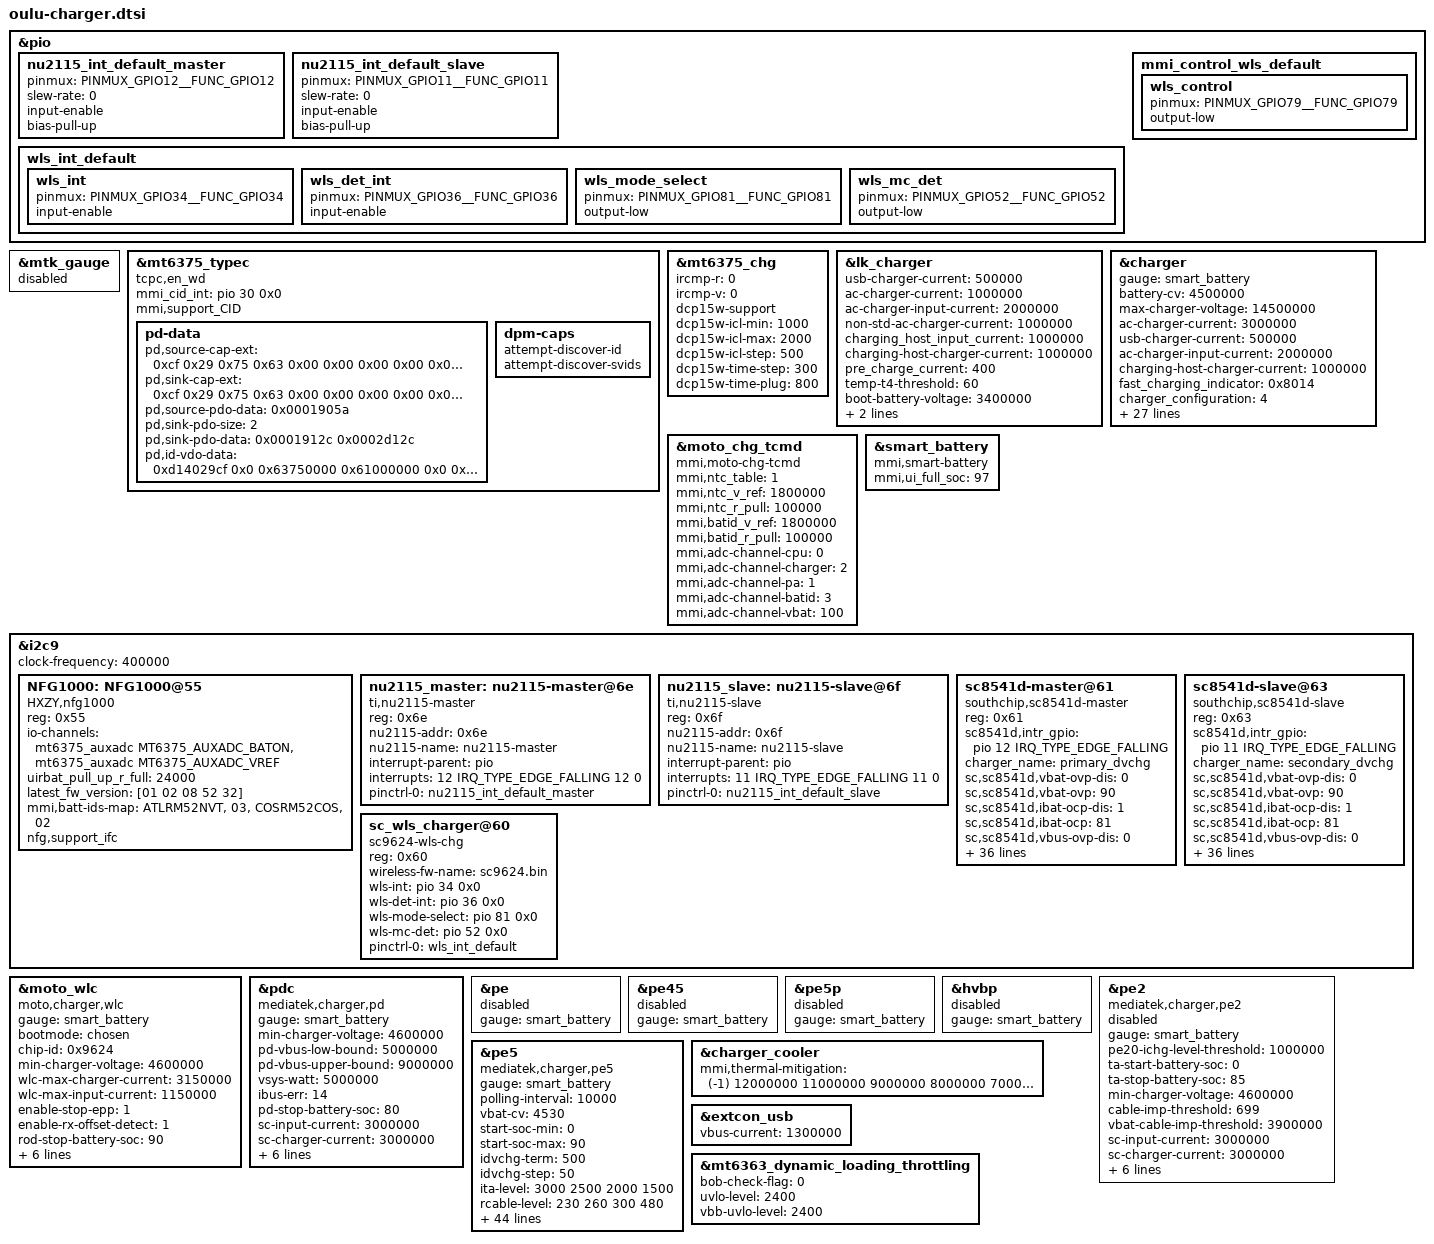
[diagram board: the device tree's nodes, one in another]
/*
 * Copyright (c) 2021 MediaTek Inc.
 *
 * This program is free software; you can redistribute it and/or modify
 * it under the terms of the GNU General Public License version 2 as
 * published by the Free Software Foundation.
 *
 * This program is distributed in the hope that it will be useful,
 * but WITHOUT ANY WARRANTY; without even the implied warranty of
 * MERCHANTABILITY or FITNESS FOR A PARTICULAR PURPOSE.  See the
 * GNU General Public License for more details.
 */
#include <dt-bindings/iio/adc/mediatek,mt6375_auxadc.h>
#include <dt-bindings/iio/adc/mediatek,mt6375_adc.h>
#include <dt-bindings/iio/mt635x-auxadc.h>

&pio {
	nu2115_int_default_master: nu2115_int_default_master {
		pinmux = <PINMUX_GPIO12__FUNC_GPIO12>;
		slew-rate= <0>;
		input-enable;
		bias-pull-up;
	};

	nu2115_int_default_slave: nu2115_int_default_slave {
		pinmux = <PINMUX_GPIO11__FUNC_GPIO11>;
		slew-rate= <0>;
		input-enable;
		bias-pull-up;
	};

	wls_int_default: wls_int_default {
		wls_int {
			pinmux = <PINMUX_GPIO34__FUNC_GPIO34>;
			input-enable;
			//bias-pull-up;
		};
		wls_det_int {
			pinmux = <PINMUX_GPIO36__FUNC_GPIO36>;
			input-enable;
			//bias-disable;
		};
		wls_mode_select {
			pinmux = <PINMUX_GPIO81__FUNC_GPIO81>;
			output-low;
		};
		wls_mc_det {
			pinmux = <PINMUX_GPIO52__FUNC_GPIO52>;
			output-low;
		};
	};

	mmi_control_wls_default: mmi_control_wls_default {
		wls_control {
			pinmux = <PINMUX_GPIO79__FUNC_GPIO79>;
			output-low;
		};
	};
};

&mtk_gauge {
	status = "disabled";
};


&mt6375_typec {
       tcpc,en_wd;
       mmi_cid_int = <&pio 30 0x0>;
       mmi,support_CID;
};

&mt6375_chg {
	ircmp-r = <0>;
	ircmp-v = <0>;

	dcp15w-support;
	dcp15w-icl-min = <1000>; //mA
	dcp15w-icl-max = <2000>; //mA
	dcp15w-icl-step = <500>; //mA
	dcp15w-time-step = <300>; //ms
	dcp15w-time-plug = <800>; //ms
};

&lk_charger {
	/* charging current */
	usb-charger-current = <500000>;
	ac-charger-current = <1000000>;
	ac-charger-input-current = <2000000>;
	non-std-ac-charger-current = <1000000>;
	charging_host_input_current = <1000000>;
	charging-host-charger-current = <1000000>;
	pre_charge_current = <400>;

	temp-t4-threshold = <60>;
	boot-battery-voltage = <3400000>;
	boot-battery-voltage-max = <3400000>;
	/*boot battery voltage when using AC charger*/
	ac_charger_boot_battery_voltage = <3300000>;
};

/*
&mtk_ctd {
	bootmode = <&chosen>;
};
*/

&charger {
	gauge = <&smart_battery>;
	battery-cv = <4500000>;
	max-charger-voltage = <14500000>;
	ac-charger-current = <3000000>;
	usb-charger-current = <500000>;
	ac-charger-input-current = <2000000>;
	charging-host-charger-current = <1000000>;

	/*pe5 && pdc && pe2 && wlc*/
	fast_charging_indicator = <0x8014>;
	/*swchg + 2CP*/
	charger_configuration= <4>;

	wireless_factory_max_current = <3000000>;
	wireless_factory_max_input_current = <600000>;

	disable-aicl;

	enable-pdtest-mode = <1>;

	mmi,enable-mux;
	mmi,typec-mos-only;

	mmi,enable-ifc;

	// mmi,mux_wls_switch_en = <&pio 99 0x0>;
	// mmi,mux_switch_enn_en = <&pio 32 0x0>;

	/* dynamic mivr */
	enable-dynamic-mivr;

	/*mmi config*/
	mmi,typec-rp-max-current = <2000000>;

	mmi,enable-charging-limit;
	mmi,upper-limit-capacity = <65>;
	mmi,lower-limit-capacity = <60>;
	mmi,min-cp-therm-current-ua = <1000000>;

	mmi,pd-pmax-mw = <68000>;
	mmi,pd_vbus_low_bound = <5000000>;
	mmi,pd_vbus_upper_bound = <9000000>;

	mmi,mmi-temp-zones = <0 4200 1020 0>,
				<10 4250 5100 2550>,
				<15 0 5100 5100>,
				<45 4250 12000 10000>,
				<45 4300 10000 8000>,
				<45 4400 8000 6000>,
				<45 4500 6000 5100>,
				<60 4200 5100 0>;
	mmi,mmi-ffc-zones = <0 4200 255>,
				<10 4500 255>,
				<15 4500 255>,
				<25 4530 930>,
				<35 4530 1018>,
				<45 4530 1389>,
				<60 4200 255>;
	mmi,mmi-normal-zones = <0 4200 255>,
				<10 4500 255>,
				<15 4500 255>,
				<25 4500 255>,
				<35 4500 255>,
				<45 4500 510>,
				<60 4200 255>;
};

/*
&mt6375_chg {
	mmi,mux_otg_switch_en = <&pio 99 0x0>;
};
*/
&moto_chg_tcmd {
	compatible = "mmi,moto-chg-tcmd";
	status = "okay";

	mmi,ntc_table = <1>;
	mmi,ntc_v_ref = <1800000>;
	mmi,ntc_r_pull = <100000>;

	mmi,batid_v_ref = <1800000>;
	mmi,batid_r_pull = <100000>;

	mmi,adc-channel-cpu = <0>;
	mmi,adc-channel-charger = <2>;
	mmi,adc-channel-pa = <1>;
	mmi,adc-channel-batid = <3>;
	mmi,adc-channel-vbat = <100>;
};

&smart_battery {
	status = "okay";
	compatible = "mmi,smart-battery";
	mmi,ui_full_soc = <97>;
};

&i2c9 {
	clock-frequency = <400000>;
	status = "okay";

	NFG1000: NFG1000@55 {
		compatible = "HXZY,nfg1000";
		reg = <0x55>;

		io-channels = <&mt6375_auxadc MT6375_AUXADC_BATON>,
		              <&mt6375_auxadc MT6375_AUXADC_VREF>;
		io-channel-names = "bat_temp", "vref";

		uirbat_pull_up_r_full = <24000>;/*24k*/

		latest_fw_version = [01 02 08 52 32];
		mmi,batt-ids-map = "ATLRM52NVT","03",
				   "COSRM52COS","02";
		nfg,support_ifc;
	};

	nu2115_master:nu2115-master@6e {
		status = "okay";
		compatible = "ti,nu2115-master";
		reg = <0x6e>;

		nu2115-addr = <0x6e>;
		nu2115-name = "nu2115-master";

		interrupt-parent = <&pio>;
		interrupts = <12 IRQ_TYPE_EDGE_FALLING 12 0>;
		interrupt-names = "nu2115_irq_master";

		pinctrl-names = "default";
		pinctrl-0 = <&nu2115_int_default_master>;
	};

	nu2115_slave:nu2115-slave@6f {
		status = "okay";
		compatible = "ti,nu2115-slave";
		reg = <0x6f>;

		nu2115-addr = <0x6f>;
		nu2115-name = "nu2115-slave";

		interrupt-parent = <&pio>;
		interrupts = <11 IRQ_TYPE_EDGE_FALLING 11 0>;
		interrupt-names = "nu2115_irq_slave";

		pinctrl-names = "default";
		pinctrl-0 = <&nu2115_int_default_slave>;
	};

	sc8541d-master@61{
		compatible = "southchip,sc8541d-master";
		reg = <0x61>;
		sc8541d,intr_gpio = <&pio 12 IRQ_TYPE_EDGE_FALLING>;
		charger_name = "primary_dvchg";

		sc,sc8541d,vbat-ovp-dis = <0>;
		sc,sc8541d,vbat-ovp = <90>; /*3840 + val * 10*/
		sc,sc8541d,ibat-ocp-dis = <1>;
		sc,sc8541d,ibat-ocp = <81>; /*val * 100*/
		sc,sc8541d,vbus-ovp-dis = <0>;
		sc,sc8541d,vbus-ovp = <3>; /*10500 + val * 500*/
		sc,sc8541d,vac-ovp-dis = <0>;
		sc,sc8541d,vac-ovp = <2>; /*0:6.5V 1:11V 2:12V 3:13V 4:14V 5~7:15V*/
		sc,sc8541d,ibus-ocp-dis = <1>;
		sc,sc8541d,ibus-ocp = <100>; /*val * 50*/
		sc,sc8541d,pmid2out-ovp-dis = <0>;
		sc,sc8541d,pmid2out-ovp = <0>; /*400 + val * 100*/
		sc,sc8541d,pmid2out-uvp-dis = <0>;
		sc,sc8541d,pmid2out-uvp = <1>; /*100 + val * 50*/
		sc,sc8541d,ibatreg = <0>; /*200 + val * 100*/
		sc,sc8541d,ibusreg = <0>; /*100 + val * 50*/
		sc,sc8541d,vbatreg = <0>; /*50 + val * 50*/
		sc,sc8541d,tdiereg = <1>; /*0:90°C 1:100°C 2:110°C 3:120°C*/
		sc,sc8541d,them-flt = <24>; /*val * 25*/
		sc,sc8541d,ibat-sns-res = <0>; /*0:2hmo 1:5hmo*/
		sc,sc8541d,pmid-pd-en = <0>;
		sc,sc8541d,vbus-pd-en = <0>;
		sc,sc8541d,work-mode = <0>; /*0: 2:1charge   1: 1:1charge
		                             2: 1:2converte 3: 1:1converte*/
		sc,sc8541d,ss-timeout = <7>; /*0:disable 1:10ms 2:20ms 3:400ms
		                            4:80ms 5:320ms 6:1.28s 7:10.24s*/
		sc,sc8541d,wd-timeout-dis = <1>;
		sc,sc8541d,wd-timeout = <0>; /*0:0.5s 1:1s 2:5s 3:30s*/
		sc,sc8541d,vout-ovp-dis = <0>;
		sc,sc8541d,vout-ovp = <1>; /*0:4700mv 1:5000mv*/
		sc,sc8541d,fsw-freq = <7>; /*500 + val * 100*/
		sc,sc8541d,pin-diag-fall-dis = <0>;
		sc,sc8541d,them-flt-dis = <1>;
		sc,sc8541d,tshut-dis = <1>;
		sc,sc8541d,ibus-ucp-dis = <0>;
		sc,sc8541d,ibat-reg-dis = <0>;
		sc,sc8541d,ibus-reg-dis = <0>;
		sc,sc8541d,vbat-reg-dis = <0>;
		sc,sc8541d,tdie-reg-dis = <1>;
		sc,sc8541d,ibat-ocp-dg = <0>; /*0:80us 1:320us 2:640us 3:5ms*/
		sc,sc8541d,ibus-ucp-fall-dg = <1>; /*0:8us 1:5ms 2:40ms 3:160ms*/
		sc,sc8541d,ibus-ocp-dg = <0>; /*0:80us 1:320us 2:640us 3:5ms*/
		sc,sc8541d,vbat-ovp-dg = <0>; /*0:8us 1:640us 2:1.28ms 3:5ms*/
	};

	sc8541d-slave@63{
		compatible = "southchip,sc8541d-slave";
		reg = <0x63>;
		sc8541d,intr_gpio = <&pio 11 IRQ_TYPE_EDGE_FALLING>;
		charger_name = "secondary_dvchg";

		sc,sc8541d,vbat-ovp-dis = <0>;
		sc,sc8541d,vbat-ovp = <90>; /*3840 + val * 10*/
		sc,sc8541d,ibat-ocp-dis = <1>;
		sc,sc8541d,ibat-ocp = <81>; /*val * 100*/
		sc,sc8541d,vbus-ovp-dis = <0>;
		sc,sc8541d,vbus-ovp = <3>; /*10500 + val * 500*/
		sc,sc8541d,vac-ovp-dis = <0>;
		sc,sc8541d,vac-ovp = <2>; /*0:6.5V 1:11V 2:12V 3:13V 4:14V 5~7:15V*/
		sc,sc8541d,ibus-ocp-dis = <1>;
		sc,sc8541d,ibus-ocp = <100>; /*val * 50*/
		sc,sc8541d,pmid2out-ovp-dis = <0>;
		sc,sc8541d,pmid2out-ovp = <0>; /*400 + val * 100*/
		sc,sc8541d,pmid2out-uvp-dis = <0>;
		sc,sc8541d,pmid2out-uvp = <1>; /*100 + val * 50*/
		sc,sc8541d,ibatreg = <0>; /*200 + val * 100*/
		sc,sc8541d,ibusreg = <0>; /*100 + val * 50*/
		sc,sc8541d,vbatreg = <0>; /*50 + val * 50*/
		sc,sc8541d,tdiereg = <1>; /*0:90°C 1:100°C 2:110°C 3:120°C*/
		sc,sc8541d,them-flt = <24>; /*val * 25*/
		sc,sc8541d,ibat-sns-res = <0>; /*0:2hmo 1:5hmo*/
		sc,sc8541d,pmid-pd-en = <0>;
		sc,sc8541d,vbus-pd-en = <0>;
		sc,sc8541d,work-mode = <0>; /*0: 2:1charge   1: 1:1charge
		                             2: 1:2converte 3: 1:1converte*/
		sc,sc8541d,ss-timeout = <7>; /*0:disable 1:10ms 2:20ms 3:400ms
		                            4:80ms 5:320ms 6:1.28s 7:10.24s*/
		sc,sc8541d,wd-timeout-dis = <1>;
		sc,sc8541d,wd-timeout = <0>; /*0:0.5s 1:1s 2:5s 3:30s*/
		sc,sc8541d,vout-ovp-dis = <0>;
		sc,sc8541d,vout-ovp = <1>; /*0:4700mv 1:5000mv*/
		sc,sc8541d,fsw-freq = <7>; /*500 + val * 100*/
		sc,sc8541d,pin-diag-fall-dis = <0>;
		sc,sc8541d,them-flt-dis = <1>;
		sc,sc8541d,tshut-dis = <1>;
		sc,sc8541d,ibus-ucp-dis = <0>;
		sc,sc8541d,ibat-reg-dis = <0>;
		sc,sc8541d,ibus-reg-dis = <0>;
		sc,sc8541d,vbat-reg-dis = <0>;
		sc,sc8541d,tdie-reg-dis = <1>;
		sc,sc8541d,ibat-ocp-dg = <0>; /*0:80us 1:320us 2:640us 3:5ms*/
		sc,sc8541d,ibus-ucp-fall-dg = <1>; /*0:8us 1:5ms 2:40ms 3:160ms*/
		sc,sc8541d,ibus-ocp-dg = <0>; /*0:80us 1:320us 2:640us 3:5ms*/
		sc,sc8541d,vbat-ovp-dg = <0>; /*0:8us 1:640us 2:1.28ms 3:5ms*/
	};

	sc_wls_charger@60 {
		compatible = "sc9624-wls-chg";
		reg = <0x60>;
		wireless-fw-name = "sc9624.bin";
		wls-int = <&pio 34 0x0>;
		wls-det-int = <&pio 36 0x0>;
		wls-mode-select = <&pio 81 0x0>;
		wls-mc-det = <&pio 52 0x0>;
		pinctrl-names = "default";
		pinctrl-0 = <&wls_int_default>;
		status = "okay";
	};
};

&moto_wlc {
	compatible = "moto,charger,wlc";
	gauge = <&smart_battery>;
	bootmode = <&chosen>;
	chip-id = <0x9624>;
	min-charger-voltage = <4600000>;
	wlc-max-charger-current = <3150000>;
	wlc-max-input-current = <1150000>;
	enable-stop-epp = <1>;
	enable-rx-offset-detect = <1>;
	/*stop rx offset detect battery soc*/
	rod-stop-battery-soc = <90>;
	mmi,wls-control-en = <&pio 79 0x0>;
	pinctrl-names = "default";
	pinctrl-0 = <&mmi_control_wls_default>;
	#cooling-cells = <2>;
	mmi,wlc-rx-mitigation = <(-1) 2500000 2000000 1800000 1200000
							1000000 800000 500000>;
	mmi,wlc-thermal-config-com = <400 1>,
				<420 2>,
				<425 3>,
				<430 4>,
				<435 5>,
				<455 6>,
				<470 7>;
};

&pdc {
	compatible = "mediatek,charger,pd";
	gauge = <&smart_battery>;

	min-charger-voltage = <4600000>;
	pd-vbus-low-bound = <5000000>;
	pd-vbus-upper-bound = <9000000>;
	vsys-watt = <5000000>;
	ibus-err = <14>;

	pd-stop-battery-soc = <80>;

	/* single charger */
	sc-input-current = <3000000>;
	sc-charger-current = <3000000>;

	/* dual charger in series*/
	dcs-input-current = <3200000>;
	dcs-chg1-charger-current = <1500000>;
	dcs-chg2-charger-current = <1500000>;

	/* dual charger */
	dual-polling-ieoc = <450000>;
	slave-mivr-diff = <100000>;
	vbat-threshold = <4150>;
};

&pe {
	status = "disabled";
	gauge = <&smart_battery>;
};

&pe45 {
	status = "disabled";
	gauge = <&smart_battery>;
};

&pe5p {
	status = "disabled";
	gauge = <&smart_battery>;
};

&hvbp {
	status = "disabled";
	gauge = <&smart_battery>;
};

&pe2 {
	status = "disabled";
	compatible = "mediatek,charger,pe2";
	gauge = <&smart_battery>;

	/* PE 2.0 */
	pe20-ichg-level-threshold = <1000000>; /* uA */
	ta-start-battery-soc = <0>;
	ta-stop-battery-soc = <85>;
	min-charger-voltage = <4600000>;

	/* cable measurement impedance */
	cable-imp-threshold = <699>;
	vbat-cable-imp-threshold = <3900000>; /* uV */

	/* single charger */
	sc-input-current = <3000000>;
	sc-charger-current = <3000000>;

	/* dual charger in series*/
	dcs-input-current = <3200000>;
	dcs-chg1-charger-current = <1500000>;
	dcs-chg2-charger-current = <1500000>;

	dual-polling-ieoc = <450000>;
	slave-mivr-diff = <100000>;
	vbat-threshold = <4150>;
};

&pe5 {
	compatible = "mediatek,charger,pe5";
	gauge = <&smart_battery>;
	polling-interval = <10000>;
	vbat-cv = <4530>;
	start-soc-min = <0>;
	start-soc-max = <90>;
	idvchg-term = <500>;
	idvchg-step = <50>;
	ita-level = <3000 2500 2000 1500>;
	rcable-level = <230 260 300 480>;
	ita-level-dual = <6200 3000 2500 2000>;
	rcable-level-dual = <180 230 260 300>;
	idvchg-ss-init = <1000>;
	idvchg-ss-step = <250>;
	idvchg-ss-step1 = <100>;
	idvchg-ss-step2 = <50>;
	idvchg-ss-step1-vbat = <4000>;
	idvchg-ss-step2-vbat = <4200>;
	ta-blanking = <400>;
	swchg-aicr = <0>;
	swchg-ichg = <1200>;
	swchg-aicr-ss-init = <400>;
	swchg-aicr-ss-step = <200>;
	swchg-off-vbat = <4250>;
	force-ta-cv-vbat = <4250>;
	chg-time-max = <10800>;
	tta-level-def = <0 0 0 0 25 50 60 70 80>;
	tta-curlmt = <0 0 0 0 0 0 0 0 0>;
	tta-recovery-area = <3>;
	tbat-level-def = <0 0 0 5 25 40 43 46 50>;
	tbat-curlmt = <0 0 0 0 0 0 0 0 0>;
	tbat-recovery-area = <3>;
	tdvchg-level-def = <0 0 0 5 25 55 60 65 70>;
	tdvchg-curlmt = <0 0 0 0 0 0 0 0 0>;
	tdvchg-recovery-area = <3>;
	tswchg-level-def = <0 0 0 5 25 65 70 75 80>;
	tswchg-curlmt = <0 0 0 0 0 0 0 0 0>;
	tswchg-recovery-area = <3>;
	ifod-threshold = <200>;
	rsw-min = <20>;
	ircmp-rbat = <40>;
	ircmp-vclamp = <0>;
	vta-cap-min = <6800>;
	vta-cap-max = <11000>;
	ita-cap-min = <1000>;
	support-ta = "pca_ta_pps", "pd_adapter";
	allow_not_check_ta_status;
	vbat-threshold = <4150>;
	min-charger-voltage = <4600000>;
	mmi_therm_cur_thres = <1000>;
	mmi_therm_vol_thres = <80>;
	mmi_therm_step = <3>;
	mmi_max_ibat = <12000>;
	mmi_max_hrst_cnt = <1>;
};

&mt6375_typec {
	pd-data {
		pd,source-cap-ext = /bits/ 8 <0xcf 0x29 0x75 0x63
					      0x00 0x00 0x00 0x00
					      0x00 0x00 0x00 0x00
					      0x00 0x00 0x00 0x00
					      0x00 0x00 0x00 0x00
					      0x00 0x00 0x01 0x04
					      0x00>;
		pd,sink-cap-ext = /bits/ 8 <0xcf 0x29 0x75 0x63
					    0x00 0x00 0x00 0x00
					    0x00 0x00 0x01 0x00
					    0x00 0x00 0x00 0x00
					    0x01 0x0b 0x01 0x0a
					    0x1b 0x00 0x00 0x00>;
		/* 5V, 900ma */
		pd,source-pdo-data = <0x0001905a>;
		/*5V, 3A 9V, 3A*/
		pd,sink-pdo-size = <2>;
		pd,sink-pdo-data = <0x0001912c 0x0002d12c> ;
		/* No DP, host + device */
		pd,id-vdo-data = <0xd14029cf 0x0 0x63750000
				0x61000000 0x0 0x41000000>;
	};

	dpm-caps {
		attempt-discover-id;
		attempt-discover-svids;
	};
};


&charger_cooler {
	mmi,thermal-mitigation = <(-1) 12000000 11000000 9000000 8000000
				7000000 6000000 5000000 4000000 3500000
				3000000 2500000 2000000 1500000 1000000>;
};

&extcon_usb {
	vbus-current = <1300000>;
};

&mt6363_dynamic_loading_throttling {
	status = "okay";
	bob-check-flag = <0>;
	uvlo-level = <2400>;
	vbb-uvlo-level = <2400>;
};
